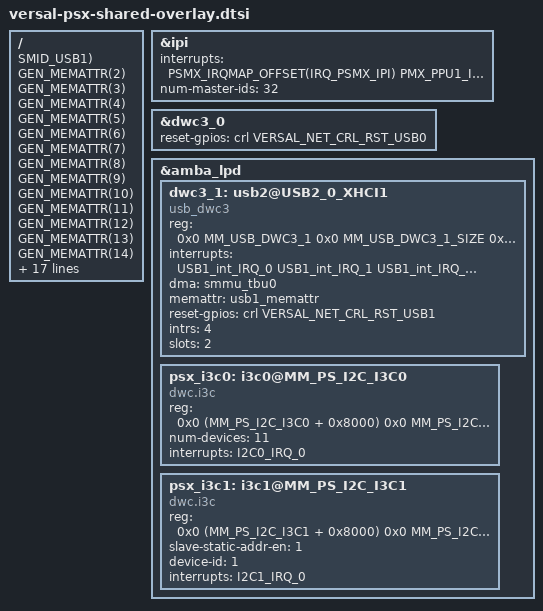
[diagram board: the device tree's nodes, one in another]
/*
 * Versal PSX Shared Overlay.
 * This contains the overlay that's suitable for the both QEMU
 * instances in a multi-arch PSX/PMX setup.
 *
 * Copyright (c) 2021, Xilinx Inc
 * All rights reserved.
 *
 * Redistribution and use in source and binary forms, with or without
 * modification, are permitted provided that the following conditions are met:
 *     * Redistributions of source code must retain the above copyright
 *       notice, this list of conditions and the following disclaimer.
 *     * Redistributions in binary form must reproduce the above copyright
 *       notice, this list of conditions and the following disclaimer in the
 *       documentation and/or other materials provided with the distribution.
 *     * Neither the name of the <organization> nor the
 *       names of its contributors may be used to endorse or promote products
 *       derived from this software without specific prior written permission.
 *
 * THIS SOFTWARE IS PROVIDED BY THE COPYRIGHT HOLDERS AND CONTRIBUTORS "AS IS" AND
 * ANY EXPRESS OR IMPLIED WARRANTIES, INCLUDING, BUT NOT LIMITED TO, THE IMPLIED
 * WARRANTIES OF MERCHANTABILITY AND FITNESS FOR A PARTICULAR PURPOSE ARE
 * DISCLAIMED. IN NO EVENT SHALL <COPYRIGHT HOLDER> BE LIABLE FOR ANY
 * DIRECT, INDIRECT, INCIDENTAL, SPECIAL, EXEMPLARY, OR CONSEQUENTIAL DAMAGES
 * (INCLUDING, BUT NOT LIMITED TO, PROCUREMENT OF SUBSTITUTE GOODS OR SERVICES;
 * LOSS OF USE, DATA, OR PROFITS; OR BUSINESS INTERRUPTION) HOWEVER CAUSED AND
 * ON ANY THEORY OF LIABILITY, WHETHER IN CONTRACT, STRICT LIABILITY, OR TORT
 * (INCLUDING NEGLIGENCE OR OTHERWISE) ARISING IN ANY WAY OUT OF THE USE OF THIS
 * SOFTWARE, EVEN IF ADVISED OF THE POSSIBILITY OF SUCH DAMAGE.
 */

#include "versal.dtsh"

#define GEN_MEMATTR(x)                                    \
MEMATTR(apu ## x ## _s, SECURE, SMID_APU ## x);      \
MEMATTR(apu ## x ## _ns, NON_SECURE, SMID_APU ## x)

#define SMID_APU2	SMID_APU_CORE2
#define SMID_APU3	SMID_APU_CORE3
#define SMID_APU4	0x268
#define SMID_APU5	0x269
#define SMID_APU6	0x26a
#define SMID_APU7	0x26b
#define SMID_APU8	0x270
#define SMID_APU9	0x271
#define SMID_APU10	0x272
#define SMID_APU11	0x273
#define SMID_APU12	0x278
#define SMID_APU13	0x279
#define SMID_APU14	0x27a
#define SMID_APU15	0x27b
#define SMID_APU16	0x280
#define SMID_APU17	0x281
#define SMID_APU18	0x282
#define SMID_APU19	0x283
#define SMID_APU20	0x288
#define SMID_APU21	0x289
#define SMID_APU22	0x28a
#define SMID_APU23	0x28b
#define SMID_APU24	0x290
#define SMID_APU25	0x291
#define SMID_APU26	0x292
#define SMID_APU27	0x293
#define SMID_APU28	0x298
#define SMID_APU29	0x299
#define SMID_APU30	0x29a
#define SMID_APU31	0x29b

#define MM_USB_DWC3_1			(MM_USB_XHCI1 + 0xC100)
#define MM_USB_DWC3_1_SIZE		0x600

#define VERSAL_NET_CRL_RST_USB0		3
#define VERSAL_NET_CRL_RST_USB1		4

&ipi {
	interrupts = <PSMX_IRQMAP_OFFSET(IRQ_PSMX_IPI)
		      PMX_PPU1_IRQMAP_OFFSET(IRQ_PPU1_INTC_PMX_IPI)
		      IPI0_IRQ_0 IPI1_IRQ_0
		      IPI2_IRQ_0 IPI3_IRQ_0
		      IPI4_IRQ_0 IPI5_IRQ_0
		      IPI6_IRQ_0
		      PMX_PPU1_IRQMAP_OFFSET(IRQ_PPU1_INTC_PMX_IPI_NOBUF)
		      IPI_MISC_IRQ_0
		      IPI_NOBUF1_IRQ_0
		      IPI_NOBUF2_IRQ_0
		      IPI_NOBUF3_IRQ_0
		      IPI_NOBUF4_IRQ_0
		      IPI_NOBUF5_IRQ_0
		      IPI_NOBUF6_IRQ_0>;
	num-master-ids = <32>;
};

/ {
	MEMATTR(usb1, NON_SECURE, SMID_USB1);

	/* APU */
        GEN_MEMATTR(2);
        GEN_MEMATTR(3);
        GEN_MEMATTR(4);
        GEN_MEMATTR(5);
        GEN_MEMATTR(6);
        GEN_MEMATTR(7);
        GEN_MEMATTR(8);
        GEN_MEMATTR(9);
        GEN_MEMATTR(10);
        GEN_MEMATTR(11);
        GEN_MEMATTR(12);
        GEN_MEMATTR(13);
        GEN_MEMATTR(14);
        GEN_MEMATTR(15);
        GEN_MEMATTR(16);
        GEN_MEMATTR(17);
        GEN_MEMATTR(18);
        GEN_MEMATTR(19);
        GEN_MEMATTR(20);
        GEN_MEMATTR(21);
        GEN_MEMATTR(22);
        GEN_MEMATTR(23);
        GEN_MEMATTR(24);
        GEN_MEMATTR(25);
        GEN_MEMATTR(26);
        GEN_MEMATTR(27);
        GEN_MEMATTR(28);
        GEN_MEMATTR(29);
        GEN_MEMATTR(30);
        GEN_MEMATTR(31);
};

&dwc3_0 {
	reset-gpios = <&crl VERSAL_NET_CRL_RST_USB0>;
};

&amba_lpd {
	dwc3_1: usb2@USB2_0_XHCI1 {
		compatible = "usb_dwc3";
		reg = <0x0 MM_USB_DWC3_1 0x0 MM_USB_DWC3_1_SIZE 0x0 0x0 MM_USB_XHCI1 0x0 MM_USB_XHCI1_SIZE 0x0>;
		interrupts = <USB1_int_IRQ_0 USB1_int_IRQ_1 USB1_int_IRQ_2 USB1_int_IRQ_3>;
		dma = <&smmu_tbu0>;
		memattr = <&usb1_memattr>;
		reset-gpios = <&crl VERSAL_NET_CRL_RST_USB1>;
		intrs = <4>;
		slots = <2>;
	};
	psx_i3c0: i3c0@MM_PS_I2C_I3C0 {
		compatible = "dwc.i3c";
		reg = <0x0 (MM_PS_I2C_I3C0 + 0x8000) 0x0 MM_PS_I2C_I3C0_SIZE 0x0>;
		num-devices = <11>;
		interrupts = <I2C0_IRQ_0>;
	};
	psx_i3c1: i3c1@MM_PS_I2C_I3C1 {
		compatible = "dwc.i3c";
		reg = <0x0 (MM_PS_I2C_I3C1 + 0x8000) 0x0 MM_PS_I2C_I3C1_SIZE 0x0>;
		slave-static-addr-en = <1>;
		device-id = <1>;
		interrupts = <I2C1_IRQ_0>;
	};
};
